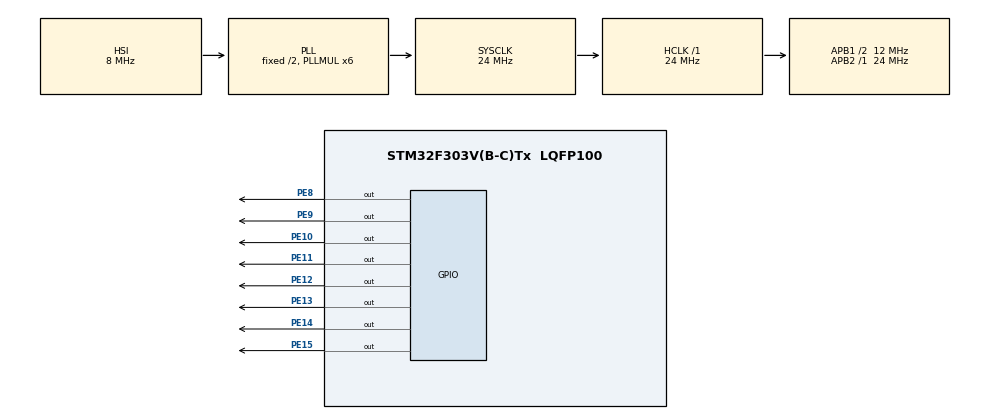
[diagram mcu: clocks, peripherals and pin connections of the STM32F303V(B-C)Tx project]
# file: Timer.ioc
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Mcu.Family=STM32F3
Mcu.Name=STM32F303V(B-C)Tx
Mcu.Package=LQFP100
NVIC.PriorityGroup=NVIC_PRIORITYGROUP_0
NVIC.TIM1_UP_TIM16_IRQn=true\:0\:0\:false\:false\:true\:true\:true\:true
NVIC.TIM6_DAC_IRQn=true\:0\:0\:false\:false\:true\:true\:true\:true
PE10.Signal=GPIO_Output
PE11.Signal=GPIO_Output
PE12.Signal=GPIO_Output
PE13.Signal=GPIO_Output
PE14.Signal=GPIO_Output
PE15.Signal=GPIO_Output
PE8.Signal=GPIO_Output
PE9.Signal=GPIO_Output
ProjectManager.HeapSize=0x200
ProjectManager.StackSize=0x400
ProjectManager.TargetToolchain=STM32CubeIDE
RCC.AHBFreq_Value=24000000
RCC.APB1CLKDivider=RCC_HCLK_DIV2
RCC.APB1Freq_Value=12000000
RCC.APB1TimFreq_Value=24000000
RCC.APB2Freq_Value=24000000
RCC.APB2TimFreq_Value=24000000
RCC.CortexFreq_Value=24000000
RCC.HCLKFreq_Value=24000000
RCC.HSE_VALUE=8000000
RCC.HSI_VALUE=8000000
RCC.LSE_VALUE=32768
RCC.PLLMUL=RCC_PLL_MUL6
RCC.SYSCLKFreq_VALUE=24000000
RCC.SYSCLKSourceVirtual=RCC_SYSCLKSOURCE_PLLCLK
RCC.USBFreq_Value=24000000
TIM16.Prescaler=80-1
TIM6.Period=999
TIM6.Prescaler=9600
VP_TIM16_VS_ClockSourceINT.Mode=Enable_Timer
VP_TIM6_VS_ClockSourceINT.Mode=Enable_Timer
board=STM32F3DISCOVERY

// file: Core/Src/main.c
/* USER CODE BEGIN Header */
/**
  ******************************************************************************
  * @file           : main.c
  * @brief          : Main program body
  ******************************************************************************
  * @attention
  *
  * Copyright (c) 2023 STMicroelectronics.
  * All rights reserved.
  *
  * This software is licensed under terms that can be found in the LICENSE file
  * in the root directory of this software component.
  * If no LICENSE file comes with this software, it is provided AS-IS.
  *
  ******************************************************************************
  */
/* USER CODE END Header */
#include "main.h"

 TIM_HandleTypeDef htim6;
TIM_HandleTypeDef htim16;

void SystemClock_Config(void);
static void MX_TIM6_Init(void);
static void MX_GPIO_Init(void);
static void MX_TIM16_Init(void);

/* USER CODE BEGIN 0 */
void HAL_TIM_PeriodElapsedCallback(TIM_HandleTypeDef *htim)
{
  /* Prevent unused argument(s) compilation warning */
  UNUSED(htim);

  if(htim==&htim16){
	  HAL_GPIO_TogglePin(GPIOE, GPIO_PIN_9);
  }
  else if(htim==&htim6){
	  HAL_GPIO_TogglePin(GPIOE, GPIO_PIN_8);
  }

  /* NOTE : This function should not be modified, when the callback is needed,
            the HAL_TIM_PeriodElapsedCallback could be implemented in the user file
   */
}

/* USER CODE END 0 */

int main(void)
{

  /* MCU Configuration--------------------------------------------------------*/

  /* Reset of all peripherals, Initializes the Flash interface and the Systick. */
  HAL_Init();

  /* Configure the system clock */
  SystemClock_Config();

  /* Initialize all configured peripherals */
  MX_TIM6_Init();
  MX_GPIO_Init();
  MX_TIM16_Init();
  /* USER CODE BEGIN 2 */
  HAL_TIM_Base_Start_IT(&htim16);
  HAL_TIM_Base_Start_IT(&htim6);
  /* USER CODE END 2 */

  /* Infinite loop */
  while (1)
  {

  }
}

void SystemClock_Config(void)
{
  RCC_OscInitTypeDef RCC_OscInitStruct = {0};
  RCC_ClkInitTypeDef RCC_ClkInitStruct = {0};

  /** Initializes the RCC Oscillators according to the specified parameters
  * in the RCC_OscInitTypeDef structure.
  */
  RCC_OscInitStruct.OscillatorType = RCC_OSCILLATORTYPE_HSI;
  RCC_OscInitStruct.HSIState = RCC_HSI_ON;
  RCC_OscInitStruct.HSICalibrationValue = RCC_HSICALIBRATION_DEFAULT;
  RCC_OscInitStruct.PLL.PLLState = RCC_PLL_ON;
  RCC_OscInitStruct.PLL.PLLSource = RCC_PLLSOURCE_HSI;
  RCC_OscInitStruct.PLL.PLLMUL = RCC_PLL_MUL6;
  if (HAL_RCC_OscConfig(&RCC_OscInitStruct) != HAL_OK)
  {
    Error_Handler();
  }

  /** Initializes the CPU, AHB and APB buses clocks
  */
  RCC_ClkInitStruct.ClockType = RCC_CLOCKTYPE_HCLK|RCC_CLOCKTYPE_SYSCLK
                              |RCC_CLOCKTYPE_PCLK1|RCC_CLOCKTYPE_PCLK2;
  RCC_ClkInitStruct.SYSCLKSource = RCC_SYSCLKSOURCE_PLLCLK;
  RCC_ClkInitStruct.AHBCLKDivider = RCC_SYSCLK_DIV1;
  RCC_ClkInitStruct.APB1CLKDivider = RCC_HCLK_DIV2;
  RCC_ClkInitStruct.APB2CLKDivider = RCC_HCLK_DIV1;

  if (HAL_RCC_ClockConfig(&RCC_ClkInitStruct, FLASH_LATENCY_0) != HAL_OK)
  {
    Error_Handler();
  }
}

static void MX_TIM6_Init(void)
{

  TIM_MasterConfigTypeDef sMasterConfig = {0};

  htim6.Instance = TIM6;
  htim6.Init.Prescaler = 9600;
  htim6.Init.CounterMode = TIM_COUNTERMODE_UP;
  htim6.Init.Period = 999;
  htim6.Init.AutoReloadPreload = TIM_AUTORELOAD_PRELOAD_DISABLE;
  if (HAL_TIM_Base_Init(&htim6) != HAL_OK)
  {
    Error_Handler();
  }
  sMasterConfig.MasterOutputTrigger = TIM_TRGO_RESET;
  sMasterConfig.MasterSlaveMode = TIM_MASTERSLAVEMODE_DISABLE;
  if (HAL_TIMEx_MasterConfigSynchronization(&htim6, &sMasterConfig) != HAL_OK)
  {
    Error_Handler();
  }

}

static void MX_TIM16_Init(void)
{

  htim16.Instance = TIM16;
  htim16.Init.Prescaler = 80-1;
  htim16.Init.CounterMode = TIM_COUNTERMODE_UP;
  htim16.Init.Period = 65535;
  htim16.Init.ClockDivision = TIM_CLOCKDIVISION_DIV1;
  htim16.Init.RepetitionCounter = 0;
  htim16.Init.AutoReloadPreload = TIM_AUTORELOAD_PRELOAD_DISABLE;
  if (HAL_TIM_Base_Init(&htim16) != HAL_OK)
  {
    Error_Handler();
  }

}

static void MX_GPIO_Init(void)
{
  GPIO_InitTypeDef GPIO_InitStruct = {0};

  /* GPIO Ports Clock Enable */
  __HAL_RCC_GPIOE_CLK_ENABLE();

  /*Configure GPIO pin Output Level */
  HAL_GPIO_WritePin(GPIOE, GPIO_PIN_8|GPIO_PIN_9|GPIO_PIN_10|GPIO_PIN_11
                          |GPIO_PIN_12|GPIO_PIN_13|GPIO_PIN_14|GPIO_PIN_15, GPIO_PIN_RESET);

  /*Configure GPIO pins : PE8 PE9 PE10 PE11
                           PE12 PE13 PE14 PE15 */
  GPIO_InitStruct.Pin = GPIO_PIN_8|GPIO_PIN_9|GPIO_PIN_10|GPIO_PIN_11
                          |GPIO_PIN_12|GPIO_PIN_13|GPIO_PIN_14|GPIO_PIN_15;
  GPIO_InitStruct.Mode = GPIO_MODE_OUTPUT_PP;
  GPIO_InitStruct.Pull = GPIO_NOPULL;
  GPIO_InitStruct.Speed = GPIO_SPEED_FREQ_LOW;
  HAL_GPIO_Init(GPIOE, &GPIO_InitStruct);

}

void Error_Handler(void)
{
  __disable_irq();
  while (1)
  {
  }
}
